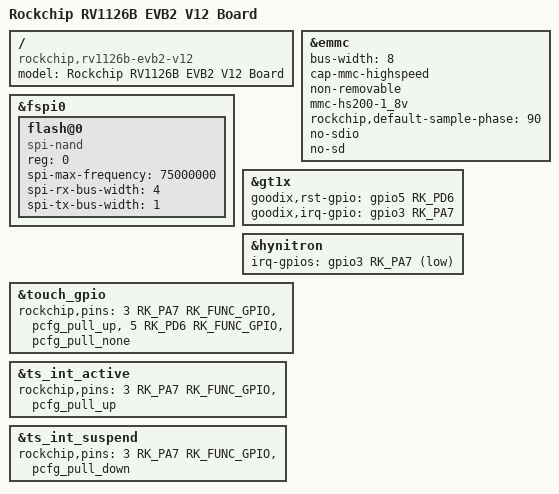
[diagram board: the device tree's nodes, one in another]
// SPDX-License-Identifier: (GPL-2.0+ OR MIT)
/*
 * Copyright (c) 2025 Rockchip Electronics Co., Ltd.
 */

/dts-v1/;
#include "rv1126b-evb2-v10.dts"

/ {
	model = "Rockchip RV1126B EVB2 V12 Board";
	compatible = "rockchip,rv1126b-evb2-v12", "rockchip,rv1126b";
};

&emmc {
	bus-width = <8>;
	cap-mmc-highspeed;
	non-removable;
	mmc-hs200-1_8v;
	rockchip,default-sample-phase = <90>;
	no-sdio;
	no-sd;
	status = "okay";
};

&fspi0 {
	status = "okay";

	flash@0 {
		compatible = "spi-nand";
		reg = <0>;
		spi-max-frequency = <75000000>;
		spi-rx-bus-width = <4>;
		spi-tx-bus-width = <1>;
	};
};

&gt1x {
	goodix,rst-gpio = <&gpio5 RK_PD6 GPIO_ACTIVE_HIGH>;
	goodix,irq-gpio = <&gpio3 RK_PA7 IRQ_TYPE_LEVEL_LOW>;
};

&hynitron {
	irq-gpios = <&gpio3 RK_PA7 GPIO_ACTIVE_LOW>;
};

&touch_gpio {
	rockchip,pins =
		<3 RK_PA7 RK_FUNC_GPIO &pcfg_pull_up>,
		<5 RK_PD6 RK_FUNC_GPIO &pcfg_pull_none>;
};

&ts_int_active {
	rockchip,pins = <3 RK_PA7 RK_FUNC_GPIO &pcfg_pull_up>;
};

&ts_int_suspend {
	rockchip,pins = <3 RK_PA7 RK_FUNC_GPIO &pcfg_pull_down>;
};
